# G32R430xx register map
Vendor: Geehy Semiconductor Co., Ltd.; Series: G32R4; File version: 1.0
CPU: CM52 r0p1, little endian, MPU, no FPU, DSP, VTOR, 4 interrupt priority bits
Registers are 32-bit, read-write, reset 0x0 unless marked. A register's access mark holds for its fields unless they carry their own. Offsets are from the block's base; [hi:lo] are bit positions; {n}, {i} and the like mark numbered series.

## GPIO — General purpose I/O
Base 0x40021800
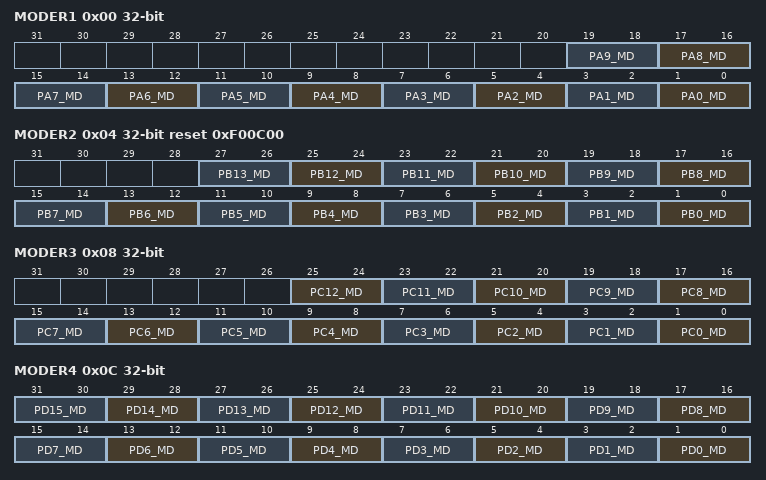
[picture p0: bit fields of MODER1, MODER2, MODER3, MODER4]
0x00 MODER1 — GPIO mode register 1
  [2n+1:2n] PA{n}_MD (n=0..9) — Work Mode Configuration
0x04 MODER2 reset 0xF00C00 — GPIO mode register 2
  [2n+1:2n] PB{n}_MD (n=0..13) — Work Mode Configuration
0x08 MODER3 — GPIO mode register 3
  [2n+1:2n] PC{n}_MD (n=0..12) — Work Mode Configuration
0x0C MODER4 — GPIO mode register 4
  [2n+1:2n] PD{n}_MD (n=0..15) — Work Mode Configuration
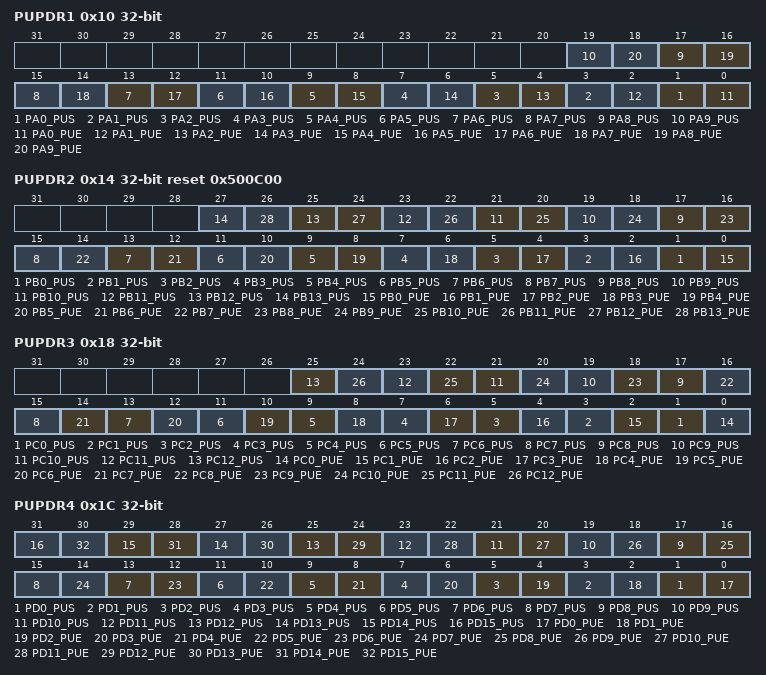
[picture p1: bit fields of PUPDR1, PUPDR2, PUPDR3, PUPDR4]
0x10 PUPDR1 — GPIO pull-up/pull-down register 1
  [2n+1] PA{n}_PUS (n=0..9) — Select from top to bottom (effective after enabling top-down selection)
  [2n] PA{n}_PUE (n=0..9) — PAD pull-up and pull-down enable
0x14 PUPDR2 reset 0x500C00 — GPIO pull-up/pull-down register 2
  [2n+1] PB{n}_PUS (n=0..13) — Select from top to bottom (effective after enabling top-down selection)
  [2n] PB{n}_PUE (n=0..13) — PAD pull-up and pull-down enable
0x18 PUPDR3 — GPIO pull-up/pull-down register 3
  [2n+1] PC{n}_PUS (n=0..12) — Select from top to bottom (effective after enabling top-down selection)
  [2n] PC{n}_PUE (n=0..12) — PAD pull-up and pull-down enable
0x1C PUPDR4 — GPIO pull-up/pull-down register 4
  [2n+1] PD{n}_PUS (n=0..15) — Select from top to bottom (effective after enabling top-down selection)
  [2n] PD{n}_PUE (n=0..15) — PAD pull-up and pull-down enable
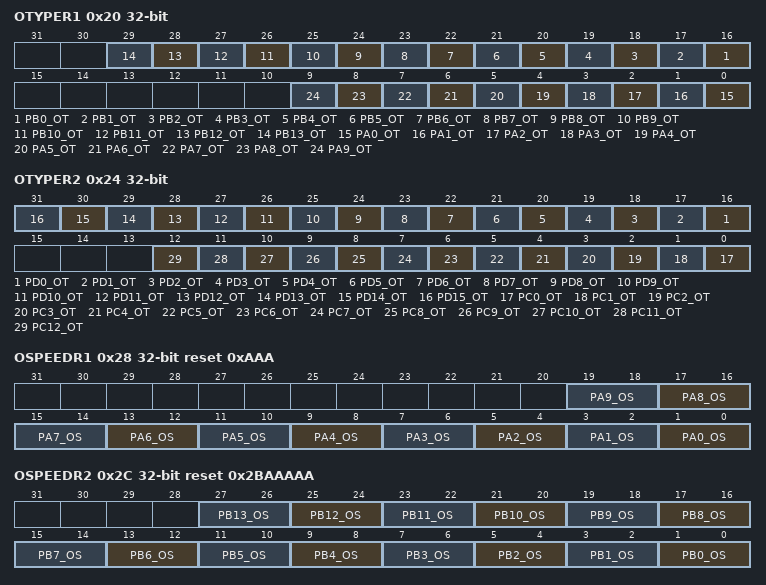
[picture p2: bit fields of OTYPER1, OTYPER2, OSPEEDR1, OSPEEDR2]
0x20 OTYPER1 — GPIO output type register 1
  [n+16] PB{n}_OT (n=0..13) — PAD output type configuration
  [n] PA{n}_OT (n=0..9) — PAD output type configuration
0x24 OTYPER2 — GPIO output type register 2
  [n+16] PD{n}_OT (n=0..15) — PAD output type configuration
  [n] PC{n}_OT (n=0..12) — PAD output type configuration
0x28 OSPEEDR1 reset 0xAAA — GPIO output speed register 1
  [2n+1:2n] PA{n}_OS (n=0..9) — PAD output speed configuration
0x2C OSPEEDR2 reset 0x2BAAAAA — GPIO output speed register 2
  [2n+1:2n] PB{n}_OS (n=0..13) — PAD output speed configuration
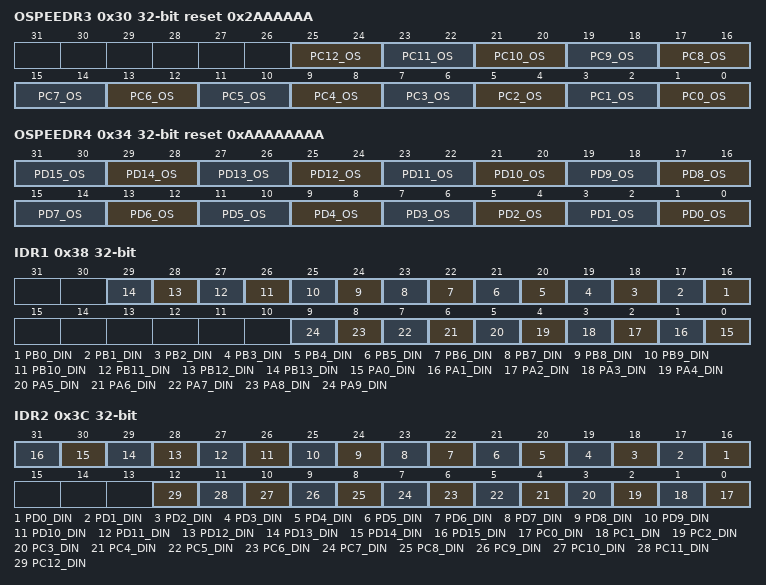
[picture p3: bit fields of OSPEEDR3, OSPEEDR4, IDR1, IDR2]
0x30 OSPEEDR3 reset 0x2AAAAAA — GPIO output speed register 3
  [2n+1:2n] PC{n}_OS (n=0..12) — PAD output speed configuration
0x34 OSPEEDR4 reset 0xAAAAAAAA — GPIO output speed register 4
  [2n+1:2n] PD{n}_OS (n=0..15) — PAD output speed configuration
0x38 IDR1 ro — GPIO input data register 1
  [n+16] PB{n}_DIN (n=0..13) — PAD input data
  [n] PA{n}_DIN (n=0..9) — PAD input data
0x3C IDR2 ro — GPIO input data register 2
  [n+16] PD{n}_DIN (n=0..15) — PAD input data
  [n] PC{n}_DIN (n=0..12) — PAD input data
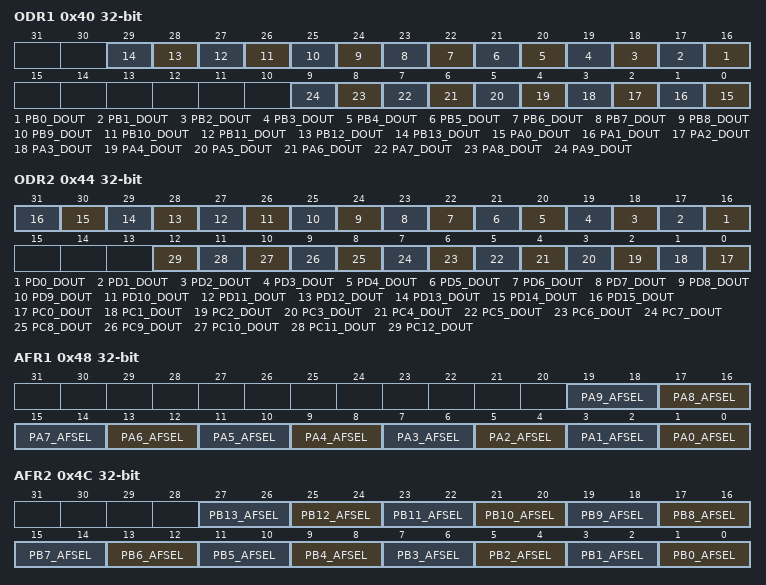
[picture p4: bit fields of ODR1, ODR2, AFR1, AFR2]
0x40 ODR1 — GPIO output data register 1
  [n+16] PB{n}_DOUT (n=0..13) — PAD output data
  [n] PA{n}_DOUT (n=0..9) — PAD output data
0x44 ODR2 — GPIO output data register 2
  [n+16] PD{n}_DOUT (n=0..15) — PAD output data
  [n] PC{n}_DOUT (n=0..12) — PAD output data
0x48 AFR1 — GPIO alternate function register 1
  [2n+1:2n] PA{n}_AFSEL (n=0..9) — PAD reuse selection
0x4C AFR2 — GPIO alternate function register 2
  [2n+1:2n] PB{n}_AFSEL (n=0..13) — PAD reuse selection
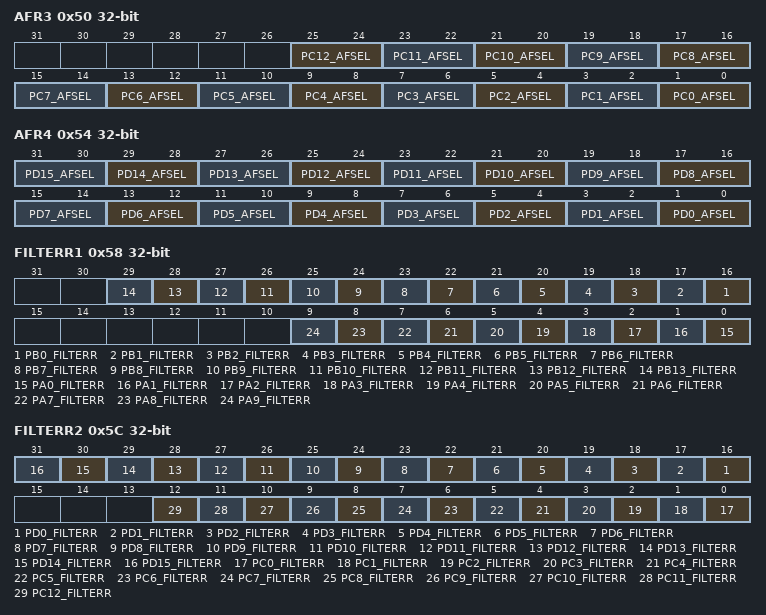
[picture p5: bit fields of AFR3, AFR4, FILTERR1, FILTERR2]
0x50 AFR3 — GPIO alternate function register 3
  [2n+1:2n] PC{n}_AFSEL (n=0..12) — PAD reuse selection
0x54 AFR4 — GPIO alternate function register 4
  [2n+1:2n] PD{n}_AFSEL (n=0..15) — PAD reuse selection
0x58 FILTERR1 — Wave Filter Enable Register 1
  [n+16] PB{n}_FILTERR (n=0..13) — PAD Filtering selection
  [n] PA{n}_FILTERR (n=0..9) — PAD Filtering selection
0x5C FILTERR2 — Wave Filter Enable Register 2
  [n+16] PD{n}_FILTERR (n=0..15) — PAD Filtering selection
  [n] PC{n}_FILTERR (n=0..12) — PAD Filtering selection
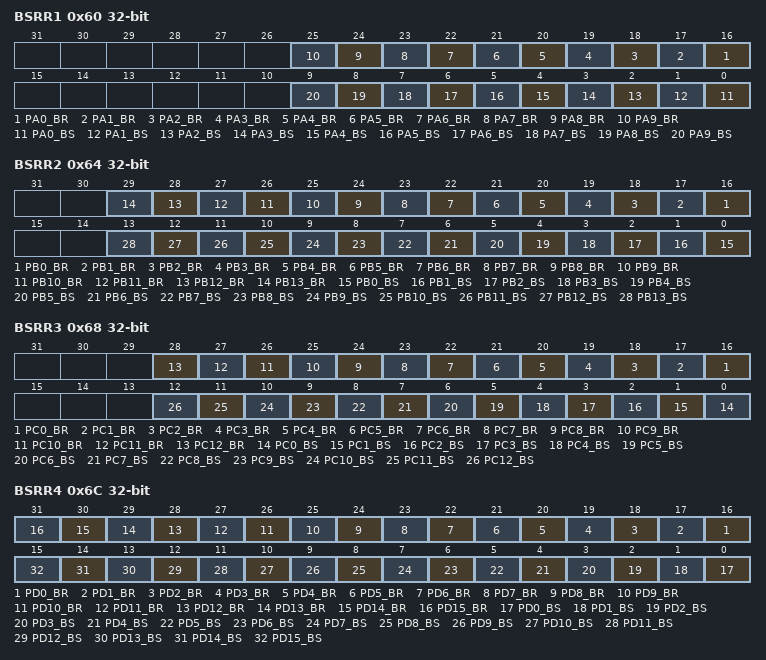
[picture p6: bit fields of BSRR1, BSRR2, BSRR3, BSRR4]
0x60 BSRR1 — Bit Set/Reset Register 1
  [n+16] PA{n}_BR (n=0..9) — PAD reset pin
  [n] PA{n}_BS (n=0..9) — PAD set pin
0x64 BSRR2 — Bit Set/Reset Register 2
  [n+16] PB{n}_BR (n=0..13) — PAD reset pin
  [n] PB{n}_BS (n=0..13) — PAD set pin
0x68 BSRR3 — Bit Set/Reset Register 3
  [n+16] PC{n}_BR (n=0..12) — PAD reset pin
  [n] PC{n}_BS (n=0..12) — PAD set pin
0x6C BSRR4 — Bit Set/Reset Register 4
  [n+16] PD{n}_BR (n=0..15) — PAD reset pin
  [n] PD{n}_BS (n=0..15) — PAD set pin
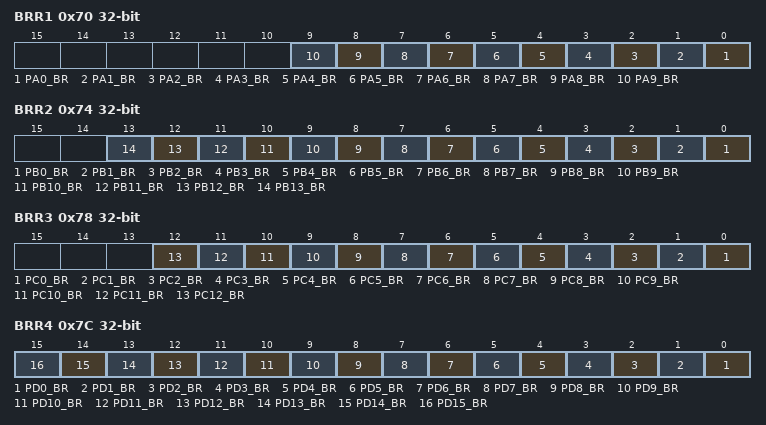
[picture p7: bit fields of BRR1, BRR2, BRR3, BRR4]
0x70 BRR1 — Bit Reset Register 1
  [n] PA{n}_BR (n=0..9) — PAD reset pin
0x74 BRR2 — Bit Reset Register 2
  [n] PB{n}_BR (n=0..13) — PAD reset pin
0x78 BRR3 — Bit Reset Register 3
  [n] PC{n}_BR (n=0..12) — PAD reset pin
0x7C BRR4 — Bit Reset Register 4
  [n] PD{n}_BR (n=0..15) — PAD reset pin
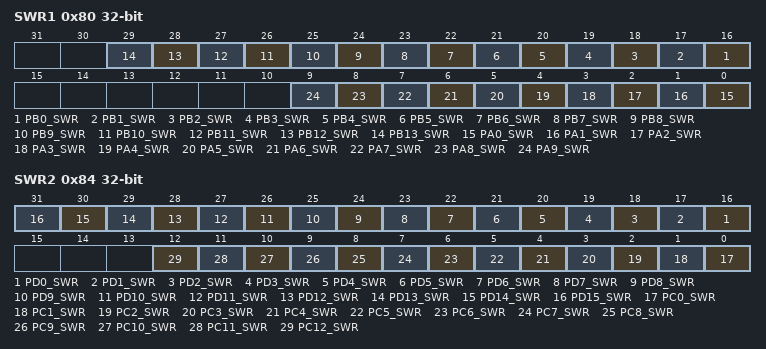
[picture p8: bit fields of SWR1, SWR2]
0x80 SWR1 — Switch Register 1
  [n+16] PB{n}_SWR (n=0..13) — Analog switch control bit
  [n] PA{n}_SWR (n=0..9) — Analog switch control bit
0x84 SWR2 — Switch Register 2
  [n+16] PD{n}_SWR (n=0..15) — Analog switch control bit
  [n] PC{n}_SWR (n=0..12) — Analog switch control bit
